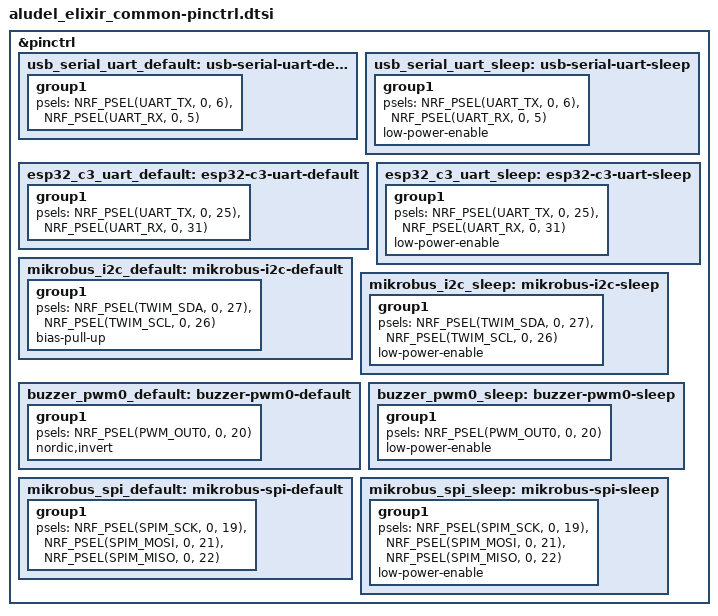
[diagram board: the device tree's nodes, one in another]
/*
 * Copyright (c) 2022 Nordic Semiconductor
 * Copyright (c) 2024 Golioth, Inc.
 * SPDX-License-Identifier: Apache-2.0
 */

&pinctrl {
	/* UART pins connected to the USB-to-UART converter */
	usb_serial_uart_default: usb-serial-uart-default {
		group1 {
			psels = <NRF_PSEL(UART_TX, 0, 6)>,
				<NRF_PSEL(UART_RX, 0, 5)>;
		};
	};

	usb_serial_uart_sleep: usb-serial-uart-sleep {
		group1 {
			psels = <NRF_PSEL(UART_TX, 0, 6)>,
				<NRF_PSEL(UART_RX, 0, 5)>;
			low-power-enable;
		};
	};

	/* UART pins connected to the ESP32-C3 */
	esp32_c3_uart_default: esp32-c3-uart-default {
		group1 {
			psels = <NRF_PSEL(UART_TX, 0, 25)>,
				<NRF_PSEL(UART_RX, 0, 31)>;
		};
	};

	esp32_c3_uart_sleep: esp32-c3-uart-sleep {
		group1 {
			psels = <NRF_PSEL(UART_TX, 0, 25)>,
				<NRF_PSEL(UART_RX, 0, 31)>;
			low-power-enable;
		};
	};

	/* I2C pins connected to the mikroBUS headers, QWIIC connectors, and
	 * onboard I2C devices.
	 */
	mikrobus_i2c_default: mikrobus-i2c-default {
		group1 {
			psels = <NRF_PSEL(TWIM_SDA, 0, 27)>,
				<NRF_PSEL(TWIM_SCL, 0, 26)>;
			bias-pull-up;
		};
	};

	mikrobus_i2c_sleep: mikrobus-i2c-sleep {
		group1 {
			psels = <NRF_PSEL(TWIM_SDA, 0, 27)>,
				<NRF_PSEL(TWIM_SCL, 0, 26)>;
			low-power-enable;
		};
	};

	/* PWM pin connected to the buzzer */
	buzzer_pwm0_default: buzzer-pwm0-default {
		group1 {
			psels = <NRF_PSEL(PWM_OUT0, 0, 20)>;
			nordic,invert;
		};
	};

	buzzer_pwm0_sleep: buzzer-pwm0-sleep {
		group1 {
			psels = <NRF_PSEL(PWM_OUT0, 0, 20)>;
			low-power-enable;
		};
	};

	/* SPI pins connected to the mikroBUS headers and external NOR flash */
	mikrobus_spi_default: mikrobus-spi-default {
		group1 {
			psels = <NRF_PSEL(SPIM_SCK, 0, 19)>,
			        <NRF_PSEL(SPIM_MOSI, 0, 21)>,
			        <NRF_PSEL(SPIM_MISO, 0, 22)>;
		};
	};

	mikrobus_spi_sleep: mikrobus-spi-sleep {
		group1 {
			psels = <NRF_PSEL(SPIM_SCK, 0, 19)>,
			        <NRF_PSEL(SPIM_MOSI, 0, 21)>,
			        <NRF_PSEL(SPIM_MISO, 0, 22)>;
			low-power-enable;
		};
	};
};
